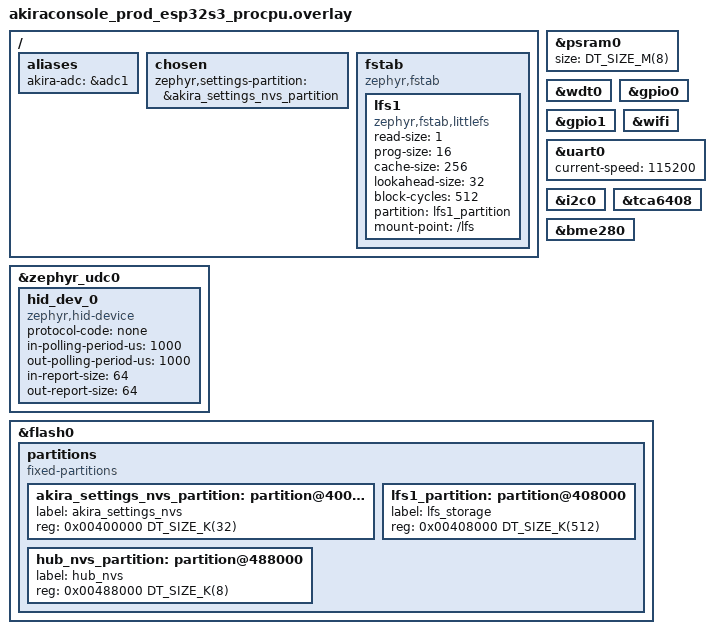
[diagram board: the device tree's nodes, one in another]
// SPDX-License-Identifier: Apache-2.0
// AkiraConsole Production — application-level overlay.
// Board hardware (pins, buses, peripherals) defined in boards/akiraconsole_prod/*.dts
// This file enables peripherals for the app build and adds display/USB config.

#include <zephyr/dt-bindings/gpio/gpio.h>

// =============================================================================
// PSRAM
// =============================================================================
&psram0 {
	size   = <DT_SIZE_M(8)>;
	status = "okay";
};

// =============================================================================
// Watchdog
// =============================================================================
&wdt0 { status = "okay"; };

// =============================================================================
// GPIO / WiFi / UART — safe for both app and MCUboot
// =============================================================================
&gpio0 { status = "okay"; };
&gpio1 { status = "okay"; };
&wifi  { status = "okay"; };
&uart0 { status = "okay"; current-speed = <115200>; };

// =============================================================================
// SPI2 — no cs-gpios override needed for ST7789V or ILI9341 modes.
// Sharp LCD (J4) override: set CONFIG_AKIRA_SHARP_DISPLAY=y — see below.
// =============================================================================
// =============================================================================
// I2C — TCA6408 (pca9538) and BME280 disabled in board DTS for MCUboot.
// Enabled here for app build only.
// =============================================================================
#ifndef CONFIG_MCUBOOT
&i2c0 { status = "okay"; };

&tca6408 {
	status = "okay";
	/delete-property/ int-gpios;
};
&bme280  { status = "okay"; };  // bosch,bme280 (I2C addr 0x77)
#endif /* !CONFIG_MCUBOOT */

// =============================================================================
// ADC alias
// =============================================================================
/ {
	aliases {
		akira-adc = &adc1;
	};
};

// =============================================================================
// Display
// Default : ST7789V via MIPI-DBI (board DTS default, no overlay changes needed).
// ILI9341 : set CONFIG_AKIRA_ILI9341_DRIVER=y in the board .conf —
//           CMakeLists.txt appends boards/akiraconsole_prod/*_ili9341.overlay.
// Sharp   : set CONFIG_AKIRA_SHARP_DISPLAY=y in the board .conf —
//           CMakeLists.txt appends boards/akiraconsole_prod/*_sharp.overlay.
// =============================================================================

// =============================================================================
// USB Device — HID interface
// =============================================================================
&zephyr_udc0 {
	status = "okay";

	hid_dev_0: hid_dev_0 {
		compatible            = "zephyr,hid-device";
		protocol-code         = "none";
		in-polling-period-us  = <1000>;
		out-polling-period-us = <1000>;
		in-report-size        = <64>;
		out-report-size       = <64>;
	};
};

// =============================================================================
// Flash partition layout — 16MB
//
//   0x000000–0x3FFFFF  MCUboot + slot0 + slot1 (partitions_0x0_amp.dtsi)
//   0x400000–0x407FFF  NVS settings 32KB   ← BT bonds, Wi-Fi credentials
//   0x408000–0x487FFF  LittleFS 512KB       ← app filesystem
//
// Partitions start at 0x400000 so OTA (slot1 at 0x170000–0x2BFFFF) never
// overwrites user data.
// =============================================================================
&flash0 {
	partitions {
		compatible = "fixed-partitions";
		#address-cells = <1>;
		#size-cells    = <1>;

		akira_settings_nvs_partition: partition@400000 {
			label = "akira_settings_nvs";
			reg   = <0x00400000 DT_SIZE_K(32)>;
		};

		lfs1_partition: partition@408000 {
			label = "lfs_storage";
			reg   = <0x00408000 DT_SIZE_K(512)>;
		};

		/* Hub credentials NVS — device_id + auth token
			* 2 × 4 KB sectors; placed after LittleFS well within 16 MB flash. */
		hub_nvs_partition: partition@488000 {
				label = "hub_nvs";
				reg   = <0x00488000 DT_SIZE_K(8)>;
		};
	};
};

/ {
	chosen {
		zephyr,settings-partition = &akira_settings_nvs_partition;
	};

	fstab {
		compatible = "zephyr,fstab";

		lfs1: lfs1 {
			compatible     = "zephyr,fstab,littlefs";
			read-size      = <1>;
			prog-size      = <16>;
			cache-size     = <256>;
			lookahead-size = <32>;
			block-cycles   = <512>;
			partition      = <&lfs1_partition>;
			mount-point    = "/lfs";
		};
	};
};
